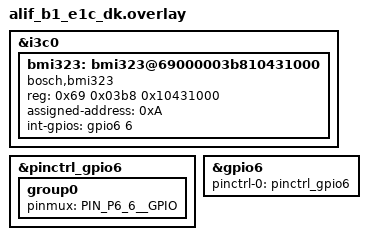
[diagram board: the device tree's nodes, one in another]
/*
 * Copyright (c) 2025 Alif Semiconductor.
 * SPDX-License-Identifier: Apache-2.0
 */

&i3c0 {
	status = "okay";

	bmi323: bmi323@69000003b810431000 {
		compatible = "bosch,bmi323";
		reg = <0x69 0x03b8 0x10431000>;
		/* Dynamic Address To Be Assigned To The Device */
		assigned-address = <0xA>;
		int-gpios	 = <&gpio6 6 GPIO_ACTIVE_HIGH>;
		status		 = "okay";
	};
};

&pinctrl_gpio6 {
	group0 {
		/* Enable only Port-6 Pin-6 */
		pinmux = <PIN_P6_6__GPIO>;
	};
};

&gpio6 {
	pinctrl-0       = <&pinctrl_gpio6>;
	pinctrl-names   = "default";
	status		= "okay";
};
